# A31M22x register map
Vendor: ABOV Semiconductor Co., Ltd.; File version: 1.0
CPU: CM0PLUS r0p1, little endian, no MPU, no FPU, VTOR, 2 interrupt priority bits
Registers are 32-bit, read-write, reset 0x0 unless marked. A register's access mark holds for its fields unless they carry their own. Offsets are from the block's base; [hi:lo] are bit positions; {n}, {i} and the like mark numbered series; 'fields as' and 'values as' point back to an identical list.

## SCU — System Control Unit
Base 0x40000000
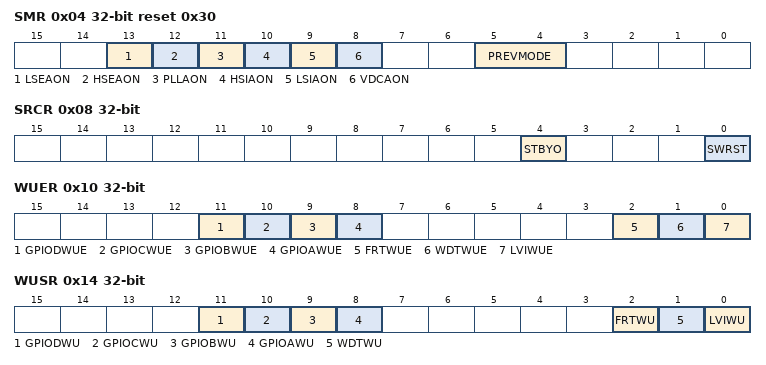
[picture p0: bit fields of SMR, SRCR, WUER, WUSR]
0x04 SMR reset 0x30 — System Mode Register
  [13] LSEAON — Auto LSE Operation in STOP Mode
  [12] HSEAON — Auto HSE Operation in STOP Mode
  [11] PLLAON — Auto PLL Operation in STOP Mode
  [10] HSIAON — Auto HSI Operation in STOP Mode
  [9] LSIAON — Auto LSI Operation in STOP Mode
  [8] VDCAON — Auto VDC Operation in STOP Mode
  [5:4] PREVMODE ro — Previous Operation Mode in Current Reset Event
    0=RUN_MODE (Previous Mode is RUN); 1=SLEEP_MODE (Previous Mode is SLEEP); 2=STOP_MODE (Previous Mode is STOP); 3=INIT_MODE (Previous Mode is INIT)
0x08 SRCR — System Reset Control Register
  [4] STBYO — STBYO pin output polarity selection bit
  [0] SWRST wo — Internal Soft Reset Enable Bit
0x10 WUER — Wake-up Source Enable Register
  [11] GPIODWUE — GPIOD Wake-up Source Enable Bit
  [10] GPIOCWUE — GPIOC Wake-up Source Enable Bit
  [9] GPIOBWUE — GPIOB Wake-up Source Enable Bit
  [8] GPIOAWUE — GPIOA Wake-up Source Enable Bit
  [2] FRTWUE — FRT Wake-up Source Enable Bit
  [1] WDTWUE — WDT Wake-up Source Enable Bit
  [0] LVIWUE — LVI Wake-up Source Enable Bit
0x14 WUSR ro — Wake-up Source Status Register
  [11] GPIODWU — GPIOD Wake-up Source Status Bit
  [10] GPIOCWU — GPIOC Wake-up Source Status Bit
  [9] GPIOBWU — GPIOB Wake-up Source Status Bit
  [8] GPIOAWU — GPIOA Wake-up Source Status Bit
  [2] FRTWU — FRT Wake-up Source Status Bit
  [1] WDTWU — WDT Wake-up Source Status Bit
  [0] LVIWU — LVI Wake-up Source Status Bit
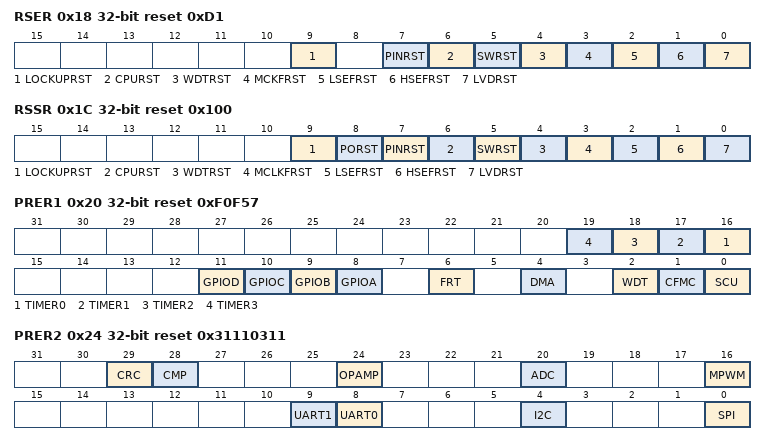
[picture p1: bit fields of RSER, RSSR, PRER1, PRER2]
0x18 RSER reset 0xD1 — Reset Source Enable Register
  [9] LOCKUPRST — CPU Lock up Reset Enable bit
  [7] PINRST — External Pin Reset Enable bit
  [6] CPURST — CPU request Reset Enable bit
  [5] SWRST — Software Reset Enable bit
  [4] WDTRST — WDT Reset Enable bit
  [3] MCKFRST — MCLK Clock Fail Reset Enable bit
  [2] LSEFRST — LSE Clock Fail Reset Enable bit
  [1] HSEFRST — HSE Clock Fail Reset Enable bit
  [0] LVDRST — LVD Fail Reset Enable bit
0x1C RSSR reset 0x100 — Reset Source Status Register
  [9] LOCKUPRST — CPU Lock up Reset Status bit
  [8] PORST — POR Status bit
  [7] PINRST — External Pin Reset Status bit
  [6] CPURST — CPU request Reset Status bit
  [5] SWRST — Software Reset Status bit
  [4] WDTRST — WDT Reset Status bit
  [3] MCLKFRST — MCLK Clock Fail Reset Status bit
  [2] LSEFRST — LSE Clock Fail Reset Status bit
  [1] HSEFRST — HSE Clock Fail Reset Status bit
  [0] LVDRST — LVD Fail Reset Status bit
0x20 PRER1 reset 0xF0F57 — Peripheral Reset Setting Register1
  [n+16] TIMER{n} (n=0..3) — TIMER{n} Reset Mask bit
  [11] GPIOD — GPIOD Reset Mask bit
  [10] GPIOC — GPIOC Reset Mask bit
  [9] GPIOB — GPIOB Reset Mask bit
  [8] GPIOA — GPIOA Reset Mask bit
  [6] FRT — FRT Reset Mask bit
  [4] DMA — DMA Reset Mask bit
  [2] WDT — WDT Reset Mask bit
  [1] CFMC — Code FMC Reset Mask bit
  [0] SCU — SCU Reset Mask bit
0x24 PRER2 reset 0x31110311 — Peripheral Reset Setting Register2
  [29] CRC — CRC Reset Mask Bit
  [28] CMP — CMP Reset Mask bit
  [24] OPAMP — OPAMP Reset Mask bit
  [20] ADC — ADC Reset Mask bit
  [16] MPWM — MPWM Reset Mask bit
  [9] UART1 — UART1 Reset Mask bit
  [8] UART0 — UART0 Reset Mask bit
  [4] I2C — I2C Reset Mask bit
  [0] SPI — SPI Reset Mask bit
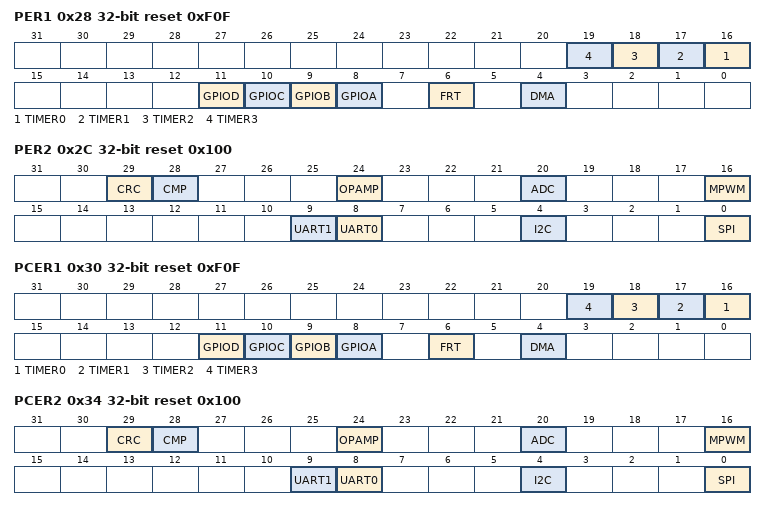
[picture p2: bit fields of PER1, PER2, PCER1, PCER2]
0x28 PER1 reset 0xF0F — Peripheral Enable Register1
  [n+16] TIMER{n} (n=0..3) — TIMER{n} Enable bit
  [11] GPIOD — GPIOD Enable bit
  [10] GPIOC — GPIOC Enable bit
  [9] GPIOB — GPIOB Enable bit
  [8] GPIOA — GPIOA Enable bit
  [6] FRT — FRT Enable bit
  [4] DMA — DMA Enable bit
0x2C PER2 reset 0x100 — Peripheral Enable Register2
  [29] CRC — CRC Enable bit
  [28] CMP — CMP Enable bit
  [24] OPAMP — OPAMP Enable bit
  [20] ADC — ADC Enable bit
  [16] MPWM — MPWM Enable bit
  [9] UART1 — UART1 Enable bit
  [8] UART0 — UART0 Enable bit
  [4] I2C — I2C Enable bit
  [0] SPI — SPI Enable bit
0x30 PCER1 reset 0xF0F — Peripheral Clock Enable Register1
  [n+16] TIMER{n} (n=0..3) — TIMER{n} Clock Enable bit
  [11] GPIOD — GPIOD Clock Enable bit
  [10] GPIOC — GPIOC Clock Enable bit
  [9] GPIOB — GPIOB Clock Enable bit
  [8] GPIOA — GPIOA Clock Enable bit
  [6] FRT — FRT Clock Enable bit
  [4] DMA — DMA Clock Enable bit
0x34 PCER2 reset 0x100 — Peripheral Clock Enable Register2
  [29] CRC — CRC Clock Enable bit
  [28] CMP — CMP Clock Enable bit
  [24] OPAMP — OPAMP Clock Enable bit
  [20] ADC — ADC Clock Enable bit
  [16] MPWM — MPWM Clock Enable bit
  [9] UART1 — UART1 Clock Enable bit
  [8] UART0 — UART0 Clock Enable bit
  [4] I2C — I2C Clock Enable bit
  [0] SPI — SPI Clock Enable bit
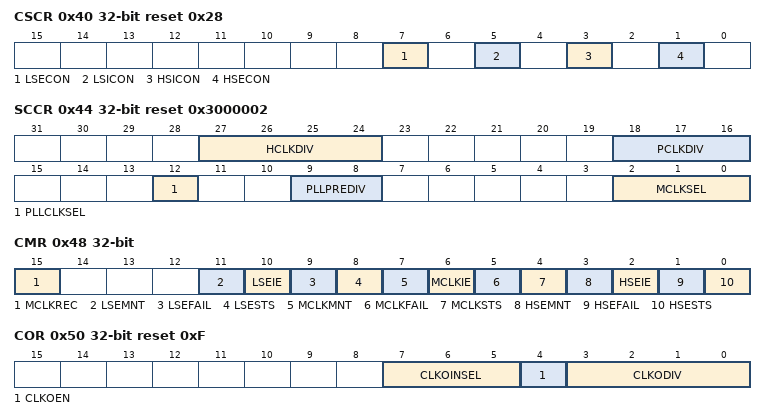
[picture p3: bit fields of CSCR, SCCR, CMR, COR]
0x40 CSCR reset 0x28 — Clock Source Control Register
  [7] LSECON — Low Speed External Oscillator Control bit
  [5] LSICON — Low Speed Internal Oscillator Control bit
  [3] HSICON — High Speed Internal Oscillator Control bit
  [1] HSECON — High Speed External Main Crystal Control bit
0x44 SCCR reset 0x3000002 — System Clock Control Register
  [27:24] HCLKDIV — HCLK Input Clock Divide bit
    9=MCLK_DIV_BY_512 (HCLK=MCLK_div_512); 8=MCLK_DIV_BY_256 (HCLK=MCLK_div_256); 7=MCLK_DIV_BY_128 (HCLK=MCLK_div_128); 6=MCLK_DIV_BY_64 (HCLK=MCLK_div_64); 5=MCLK_DIV_BY_32 (HCLK=MCLK_div_32); 4=MCLK_DIV_BY_16 (HCLK=MCLK_div_16); 3=MCLK_DIV_BY_8 (HCLK=MCLK_div_8); 2=MCLK_DIV_BY_4 (HCLK=MCLK_div_4); 1=MCLK_DIV_BY_2 (HCLK=MCLK_div_2); 0=MCLK_DIV_BY_1 (HCLK=MCLK_div_1)
  [18:16] PCLKDIV — PCLK Input Clock Divide bit
    4=HCLK_DIV_BY_16 (PCLK=HCLK_div_16); 3=HCLK_DIV_BY_8 (PCLK=HCLK_div_8); 2=HCLK_DIV_BY_4 (PCLK=HCLK_div_4); 1=HCLK_DIV_BY_2 (PCLK=HCLK_div_2); 0=MCLK_DIV_BY_1 (HCLK=MCLK_div_1)
  [12] PLLCLKSEL — PLL Input Clock Selection bit
  [9:8] PLLPREDIV — PLL Input Clock Divide bit
    3=PLLCLKSEL_DIV_BY_8 (PLL Input Clock Div 8); 2=PLLCLKSEL_DIV_BY_4 (PLL Input Clock Div 4); 1=PLLCLKSEL_DIV_BY_2 (PLL Input Clock Div 2); 0=PLLCLKSEL_DIV_BY_1 (PLL Input Clock Div 1)
  [2:0] MCLKSEL — System Clock Selection bit
    7=PLL (System Clock is PLL); 6=HSE (System Clock is HSE); 2=HSI (System Clock is HSI); 1=LSE (System Clock is LSE); 0=LSI (System Clock is LSI)
0x48 CMR — Clock Monitoring Register
  [15] MCLKREC — MCLKREC Error Auto Recovery Enable bit
  [11] LSEMNT — LSE Monitoring Enable bit
  [10] LSEIE — LSE Fail Interrupt Enable bit
  [9] LSEFAIL — LSE Fail Interrupt Flag bit
  [8] LSESTS ro — LSE Status bit
  [7] MCLKMNT — MCLK Monitoring Enable bit
  [6] MCLKIE — MCLK Fail Interrupt Enable bit
  [5] MCLKFAIL — MCLK Fail Interrupt Flag bit
  [4] MCLKSTS ro — MCLK Status bit
  [3] HSEMNT — HSE Monitoring Enable bit
  [2] HSEIE — HSE Fail Interrupt Enable bit
  [1] HSEFAIL — HSE Fail Interrupt Flag bit
  [0] HSESTS ro — HSE Status bit
0x50 COR reset 0xF — Clock Output Register
  [7:5] CLKOINSEL — Ouput Clock Selection bit
    7=PLL (Output clock is PLL); 6=HSE (Output clock is HSE); 5=HSI (Output clock is HSI); 4=MCLK (Output clock is MCLK); 1=LSE (Output clock is LSE); 0=LSI (Output clock is LSI)
  [4] CLKOEN — Clock Output Enable bit
  [3:0] CLKODIV — Clock Output Divide Setting bit
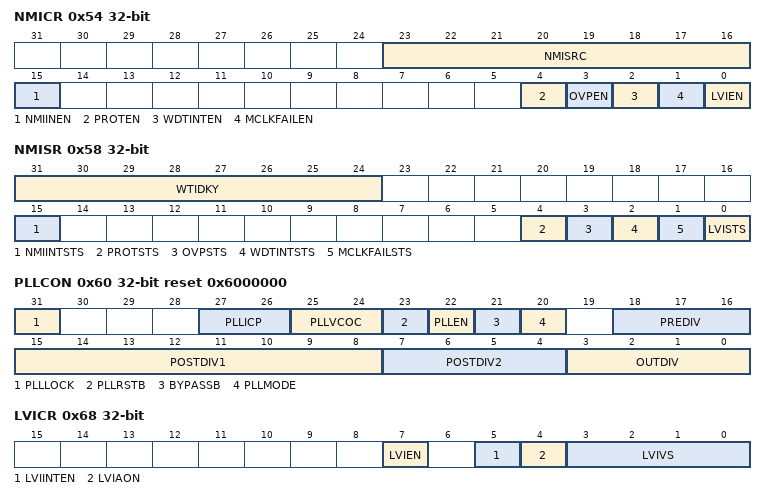
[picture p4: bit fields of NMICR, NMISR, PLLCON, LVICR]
0x54 NMICR — NMI Control Register
  [23:16] NMISRC — NMI Source Selection bits
  [15] NMIINEN — NMI Interrupt Enable bit
  [4] PROTEN — MPWM Protection Interrupt Enable bit for NMI Interrupt
  [3] OVPEN — MPWM Over Voltage Interrupt Enable bit for NMI Interrupt
  [2] WDTINTEN — WDT Interrupt Enable bit for NMI Interrupt
  [1] MCLKFAILEN — MCLK Fail Interrupt Enable bit for NMI Interrupt
  [0] LVIEN — LVI Interrupt Enable bit for NMI Interrupt
0x58 NMISR — NMI Status Register
  [31:24] WTIDKY wo — NMI Status Register Write Identification Key (0x8C)
  [15] NMIINTSTS ro — NMI Interrupt Flag bit
  [4] PROTSTS — MPWM Protection Interrupt Flag bit
  [3] OVPSTS — MPWM Over Voltage Protection Interrupt Flag bit
  [2] WDTINTSTS — WDT Interrupt Flag bit
  [1] MCLKFAILSTS — MCLK Fail Interrupt Flag bit
  [0] LVISTS — LVD Fail Interrupt Flag bit
0x60 PLLCON reset 0x6000000 — PLL Control Register
  [31] PLLLOCK ro — PLL Lock Status Bit
  [27:26] PLLICP — PLL Charge Pump Current Option
    0=5uA (Charge Pump Current); 1=10uA (Charge Pump Current); 2=15uA (Charge Pump Current); 3=20uA (Charge Pump Current)
  [25:24] PLLVCOC — PLL VCO Bias Current Option
    0=1div4 (VCO Bias Current X 1/4); 1=1div2 (VCO Bias Current X 1/2); 2=VCO Bias Current X 1; 3=VCO Bias Current X 2
  [23] PLLRSTB — PLL Reset bit
  [22] PLLEN — PLL Enable bit
  [21] BYPASSB — PLL Bypass Bit
  [20] PLLMODE — PLL VCO Mode Selection bit
  [18:16] PREDIV — FIN Predivider bit
  [15:8] POSTDIV1 — PLL Feedback Control 1(N1) bit
  [7:4] POSTDIV2 — PLL Feedback Control 2(N2) bit
  [3:0] OUTDIV — Output Divider Control(P) bit
0x64 VDCCON reset 0x7F — VDC Control Register
  [7:0] VDCWDLY — VDC Warm-up Delay Count Value Bit
0x68 LVICR — Low Voltage Indicator Interrupt Control Register
  [7] LVIEN — LVI Enable bit
  [5] LVIINTEN — LVI Interrupt Enable bit
  [4] LVIAON — LVI Stop Mode Enable bit
  [3:0] LVIVS — LVI Interrupt Voltage Selection Bit
    9=3.04V; 10=3.18V; 11=3.59V; 12=3.72V; 13=4.03V; 14=4.20V; 15=4.48V
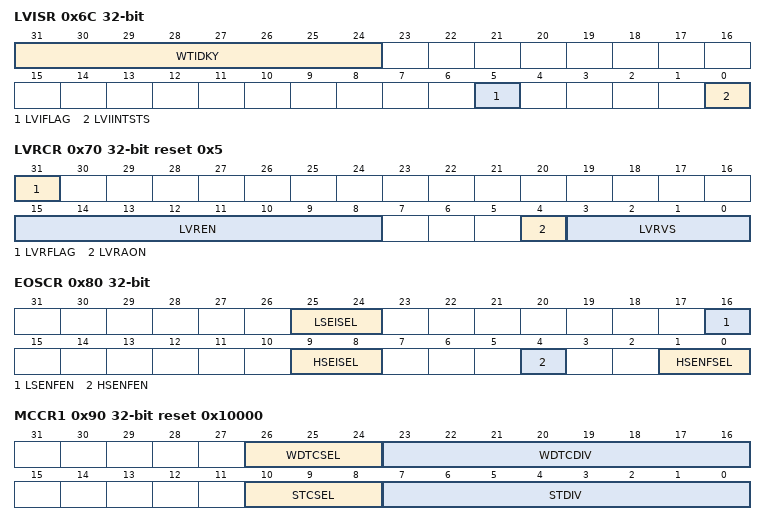
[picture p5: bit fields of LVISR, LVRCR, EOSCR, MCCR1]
0x6C LVISR — Low Voltage Indicator Interrupt Status Register
  [31:24] WTIDKY wo — Write Identification Key
  [5] LVIFLAG — LVI interrupt flag
  [0] LVIINTSTS ro — Whether or not the LVI Interrupt is active (raw data)
0x70 LVRCR reset 0x5 — Low Voltage Detect Reset Control Register
  [31] LVRFLAG ro — LVR Reset Flag bit
  [15:8] LVREN — LVR Reset Enable bit
  [4] LVRAON — LVR Reset Enable bit
  [3:0] LVRVS — LVR Reset Voltage Selection Bit
    5=2.12V; 6=2.30V; 7=2.47V; 8=2.67V; 9=3.04V; 10=3.18V; 11=3.59V; 12=3.72V; 13=4.03V; 14=4.20V; 15=4.48V
0x80 EOSCR (reset mask 0xFFFF) — External Oscillator Control Register
  [25:24] LSEISEL — ESOSC Current Capability Selection
  [16] LSENFEN — ESOSC Noise Filter Enable Bit
  [9:8] HSEISEL — EOSC Current Capability Selection
  [4] HSENFEN — EOSC Noise Filter Enable Bit
  [1:0] HSENFSEL — EOSC Noise Filter Selection
0x90 MCCR1 reset 0x10000 — MISC Clock Control Register1
  [26:24] WDTCSEL — WDT Clock Source Selection bit
    7=PLL (Clock Source is PLL); 6=HSE (Clock Source is HSE); 5=HSI (Clock Source is HSI); 4=MCLK (Clock Source is MCLK); 1=LSE (Clock Source is LSE); 0=LSI (Clock Source is LSI)
  [23:16] WDTCDIV — WDT Clock N Divider
  [10:8] STCSEL — SYSTIC Clock Source Selection bit
    values as WDTCSEL
  [7:0] STDIV — SYSTIC Clock N Divider
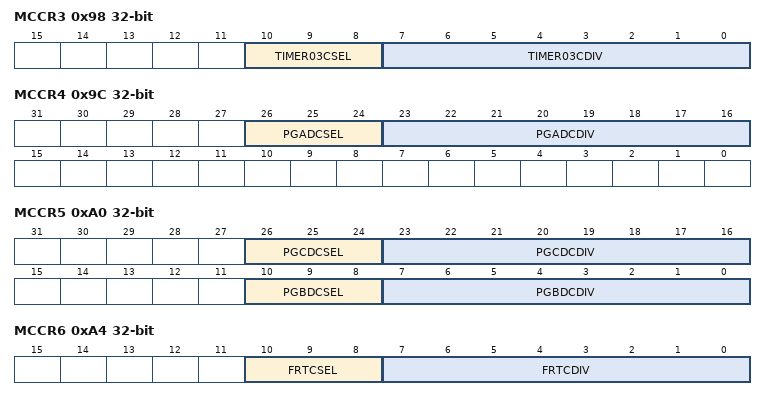
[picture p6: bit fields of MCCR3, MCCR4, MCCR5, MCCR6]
0x98 MCCR3 — MISC Clock Control Register3
  [10:8] TIMER03CSEL — TIMER 0~3 Clock Source Selection bit
    values as MCCR1.WDTCSEL
  [7:0] TIMER03CDIV — TIMER 0~3 Clock N Divider
0x9C MCCR4 — MISC Clock Control Register4
  [26:24] PGADCSEL — Port A Debounce Clock Source Selection Bit
    values as MCCR1.WDTCSEL
  [23:16] PGADCDIV — Port A debounce Clock N Divider
0xA0 MCCR5 — MISC Clock Control Register5
  [26:24] PGCDCSEL — Port C Debounce Clock Source Selection bit
    values as MCCR1.WDTCSEL
  [23:16] PGCDCDIV — Port C debounce Clock N Divider
  [10:8] PGBDCSEL — Port B debounce Clock Source Selection Bit
    values as MCCR1.WDTCSEL
  [7:0] PGBDCDIV — Port B debounce Clock N Divider
0xA4 MCCR6 — MISC Clock Control Register6
  [10:8] FRTCSEL — FRT Clock Source Selection Bit
    values as MCCR1.WDTCSEL
  [7:0] FRTCDIV — FRT Clock N Divider
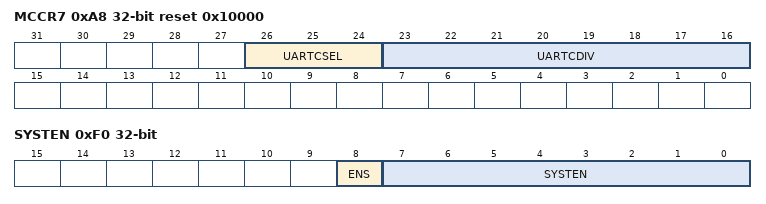
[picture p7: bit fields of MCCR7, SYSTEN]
0xA8 MCCR7 reset 0x10000 — MISC Clock Control Register7
  [26:24] UARTCSEL — UART Clock Source Selection Bit
    values as MCCR1.WDTCSEL
  [23:16] UARTCDIV — UART Clock N Divider
0xF0 SYSTEN — System Access Enable Register
  [8] ENS ro — SCU Register Access Enable Status Bit
  [7:0] SYSTEN wo — SCU Register Access Enable bit (write 0x57 and 0x75)
